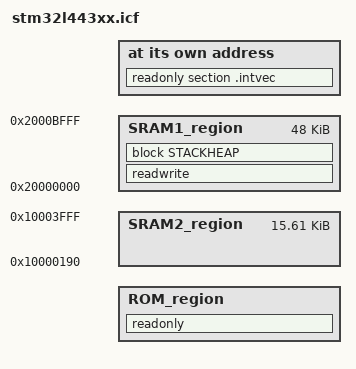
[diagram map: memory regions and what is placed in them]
if (!isdefinedsymbol(MBED_APP_START)) { define symbol MBED_APP_START = 0x08000000; }
if (!isdefinedsymbol(MBED_APP_SIZE)) { define symbol MBED_APP_SIZE = 0x40000; }

/* [ROM = 256kb = 0x40000] */
define symbol __intvec_start__     = MBED_APP_START;
define symbol __region_ROM_start__ = MBED_APP_START;
define symbol __region_ROM_end__   = MBED_APP_START + MBED_APP_SIZE - 1;

/* [RAM = 48kb + 16kb = 0xC000] */
/* Vector table dynamic copy: Total: 99 vectors * 4 = 396 bytes (0x18C) to be reserved in RAM */
define symbol __NVIC_start__          = 0x10000000;
define symbol __NVIC_end__            = 0x1000018F; /* Add 4 more bytes to be aligned on 8 bytes */
define symbol __region_SRAM2_start__  = 0x10000190;
define symbol __region_SRAM2_end__    = 0x10003FFF;
define symbol __region_SRAM1_start__  = 0x20000000;
define symbol __region_SRAM1_end__    = 0x2000BFFF;

/* Memory regions */
define memory mem with size = 4G;
define region ROM_region = mem:[from __region_ROM_start__ to __region_ROM_end__];
define region SRAM2_region = mem:[from __region_SRAM2_start__ to __region_SRAM2_end__];
define region SRAM1_region = mem:[from __region_SRAM1_start__ to __region_SRAM1_end__];

if (!isdefinedsymbol(MBED_BOOT_STACK_SIZE)) {
    define symbol MBED_BOOT_STACK_SIZE = 0x400;
}

define symbol __size_cstack__ = MBED_BOOT_STACK_SIZE;
define symbol __size_heap__   = 0x4000;
define block CSTACK    with alignment = 8, size = __size_cstack__   { };
define block HEAP      with alignment = 8, size = __size_heap__     { };
define block STACKHEAP with fixed order { block HEAP, block CSTACK };

initialize by copy with packing = zeros { readwrite };
do not initialize  { section .noinit };

place at address mem:__intvec_start__ { readonly section .intvec };

place in ROM_region   { readonly };
place in SRAM1_region   { readwrite, block STACKHEAP };
place in SRAM2_region { };
